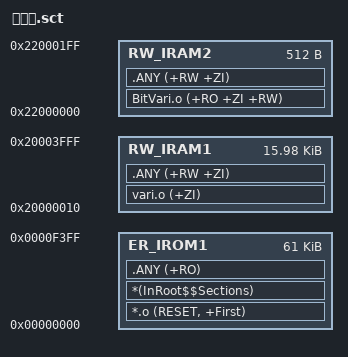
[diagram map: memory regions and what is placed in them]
; *************************************************************
; *** Scatter-Loading Description File generated by uVision ***
; *************************************************************

LR_IROM1 0x0000000 0x0000F400  {    ; load region size_region
  ER_IROM1 0x00000000 0x0000F400  {  ; load address = execution address
   *.o (RESET, +First)
   *(InRoot$$Sections)
   .ANY (+RO)
  }
  RW_IRAM1 0x20000010 0x00003FF0  {  ; RW data
    vari.o (+ZI)
   .ANY (+RW +ZI)
  }
  RW_IRAM2 0x22000000 0x00000200  {
    BitVari.o (+RO +ZI +RW)
   .ANY (+RW +ZI)
  }
}

